VERSION "created by canmatrix"

NS_ :

BS_:

BU_:

BO_ 257 SeatbeltMsg: 8 Vector__XXX
 SG_ SeatbeltStatus : 0|1@1+ (1,0) [0|1] "" Vector__XXX
 SG_ SeatbeltLock : 1|1@1+ (1,0) [0|1] "" Vector__XXX

BO_ 258 AirbagMsg: 8 Vector__XXX
 SG_ AirbagStatus : 0|2@1+ (1,0) [0|3] "" Vector__XXX
 SG_ AirbagCondition : 2|1@1+ (1,0) [0|1] "" Vector__XXX

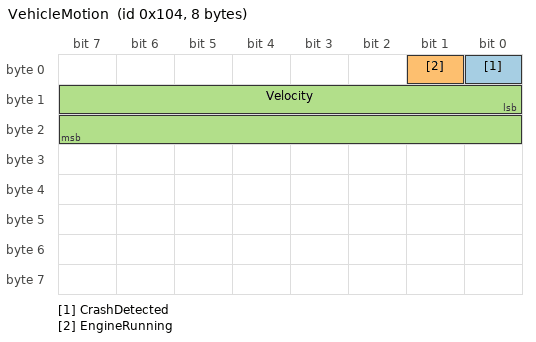
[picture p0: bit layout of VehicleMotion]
BO_ 260 VehicleMotion: 8 Vector__XXX
 SG_ CrashDetected : 0|1@1+ (1,0) [0|1] "" Vector__XXX
 SG_ EngineRunning : 1|1@1+ (1,0) [0|1] "" Vector__XXX
 SG_ Velocity : 8|16@1+ (0.1,0) [0|65535] "km/h" Vector__XXX

BO_ 261 BrakeMsg: 8 Vector__XXX
 SG_ BrakeStatus : 0|1@1+ (1,0) [0|1] "" Vector__XXX

BO_ 262 AccelarationMsg: 8 Vector__XXX
 SG_ Acceleration : 0|16@1+ (0.1,0) [0|65535] "m/s2" Vector__XXX

CM_ SG_ 257 SeatbeltStatus "Status of wether Seatbelt is worn or not";
CM_ SG_ 257 SeatbeltLock "Status of wether Seatbelt is Locked";
CM_ SG_ 258 AirbagStatus "Echos the state of the Airbag Condition";
CM_ SG_ 258 AirbagCondition "state of the Airbag Health";
CM_ SG_ 260 CrashDetected "Status of wether crash is detected or not";
CM_ SG_ 260 EngineRunning "Echos Engine Running Status";
CM_ SG_ 260 Velocity "Value of the Vehicles Velocity";
CM_ SG_ 261 BrakeStatus "Status of wether Brake is applied or not";
CM_ SG_ 262 Acceleration "Value of the Acceleration Applaid";

VAL_ 257 SeatbeltStatus 0 "NotWorn" 1 "Worn";
VAL_ 257 SeatbeltLock 0 "UnLock" 1 "Lock";
VAL_ 258 AirbagStatus 0 "Ready" 1 "NotReady" 2 "Released";
VAL_ 258 AirbagCondition 0 "Damage" 1 "Healthy";
VAL_ 260 CrashDetected 0 "CrashFree" 1 "Crash";
VAL_ 260 EngineRunning 0 "NotRunning" 1 "Running";
VAL_ 261 BrakeStatus 0 "BrakeNotApplied" 1 "BrakeApplied";
